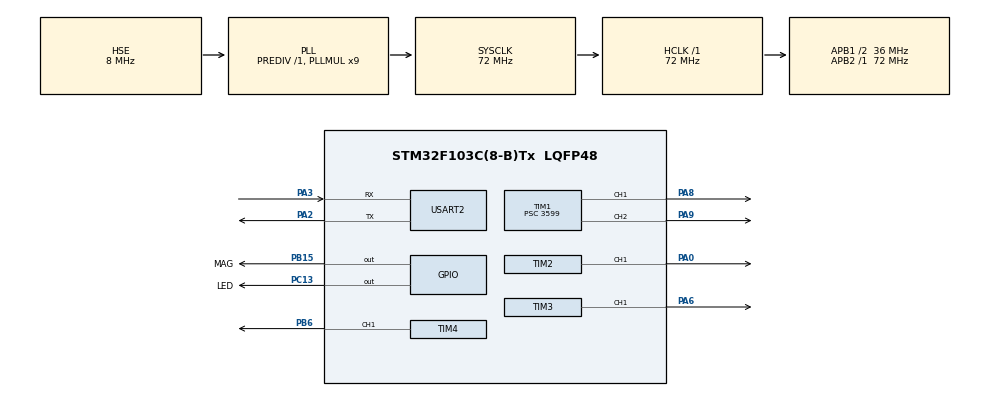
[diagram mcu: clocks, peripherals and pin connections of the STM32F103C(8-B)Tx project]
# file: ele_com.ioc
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Mcu.Family=STM32F1
Mcu.Name=STM32F103C(8-B)Tx
Mcu.Package=LQFP48
NVIC.PriorityGroup=NVIC_PRIORITYGROUP_4
NVIC.USART2_IRQn=true\:0\:0\:true\:false\:true\:true\:true\:true
PA0-WKUP.Signal=S_TIM2_CH1_ETR
PA13.Mode=Serial_Wire
PA13.Signal=SYS_JTMS-SWDIO
PA14.Mode=Serial_Wire
PA14.Signal=SYS_JTCK-SWCLK
PA2.Mode=Asynchronous
PA2.Signal=USART2_TX
PA3.Mode=Asynchronous
PA3.Signal=USART2_RX
PA6.Signal=S_TIM3_CH1
PA8.Signal=S_TIM1_CH1
PA9.Signal=S_TIM1_CH2
PB15.GPIO_Label=MAG
PB15.Signal=GPIO_Output
PB6.Signal=S_TIM4_CH1
PC13-TAMPER-RTC.GPIO_Label=LED
PC13-TAMPER-RTC.PinState=GPIO_PIN_SET
PC13-TAMPER-RTC.Signal=GPIO_Output
PD0-OSC_IN.Mode=HSE-External-Oscillator
PD0-OSC_IN.Signal=RCC_OSC_IN
PD1-OSC_OUT.Mode=HSE-External-Oscillator
PD1-OSC_OUT.Signal=RCC_OSC_OUT
ProjectManager.HeapSize=0x200
ProjectManager.StackSize=0x400
ProjectManager.TargetToolchain=STM32CubeIDE
RCC.AHBFreq_Value=72000000
RCC.APB1CLKDivider=RCC_HCLK_DIV2
RCC.APB1Freq_Value=36000000
RCC.APB1TimFreq_Value=72000000
RCC.APB2Freq_Value=72000000
RCC.APB2TimFreq_Value=72000000
RCC.HCLKFreq_Value=72000000
RCC.PLLMUL=RCC_PLL_MUL9
RCC.PLLSourceVirtual=RCC_PLLSOURCE_HSE
RCC.SYSCLKFreq_VALUE=72000000
RCC.SYSCLKSource=RCC_SYSCLKSOURCE_PLLCLK
RCC.USBFreq_Value=72000000
SH.S_TIM1_CH1.0=TIM1_CH1,PWM Generation1 CH1
SH.S_TIM1_CH2.0=TIM1_CH2,PWM Generation2 CH2
SH.S_TIM2_CH1_ETR.0=TIM2_CH1,PWM Generation1 CH1
SH.S_TIM3_CH1.0=TIM3_CH1,PWM Generation1 CH1
SH.S_TIM4_CH1.0=TIM4_CH1,PWM Generation1 CH1
TIM1.AutoReloadPreload=TIM_AUTORELOAD_PRELOAD_ENABLE
TIM1.Channel-PWM\ Generation1\ CH1=TIM_CHANNEL_1
TIM1.Channel-PWM\ Generation2\ CH2=TIM_CHANNEL_2
TIM1.OCPolarity_2=TIM_OCPOLARITY_LOW
TIM1.Period=399
TIM1.Prescaler=3599
TIM2.Channel-PWM\ Generation1\ CH1=TIM_CHANNEL_1
TIM2.Period=399
TIM2.Prescaler=3599
TIM3.Channel-PWM\ Generation1\ CH1=TIM_CHANNEL_1
TIM3.Period=399
TIM3.Prescaler=3599
TIM4.Channel-PWM\ Generation1\ CH1=TIM_CHANNEL_1
TIM4.Period=399
TIM4.Prescaler=3599
USART2.VirtualMode=VM_ASYNC
board=custom

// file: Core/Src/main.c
/* USER CODE BEGIN Header */
/**
  ******************************************************************************
  * @file           : main.c
  * @brief          : Main program body
  ******************************************************************************
  * @attention
  *
  * Copyright (c) 2024 STMicroelectronics.
  * All rights reserved.
  *
  * This software is licensed under terms that can be found in the LICENSE file
  * in the root directory of this software component.
  * If no LICENSE file comes with this software, it is provided AS-IS.
  *
  ******************************************************************************
  */
/* USER CODE END Header */
#include "main.h"
#include "tim.h"
#include "usart.h"
#include "gpio.h"

/* USER CODE BEGIN Includes */

#include "Kine.h"
#include "servo.h"
#include "stm32f1xx_ll_rcc.h"
/* USER CODE END Includes */

void SystemClock_Config(void);

/* USER CODE BEGIN 0 */
unsigned char data[5] = {0};
/* USER CODE END 0 */

int main(void)
{

  /* MCU Configuration--------------------------------------------------------*/

  /* Reset of all peripherals, Initializes the Flash interface and the Systick. */
  HAL_Init();

  /* Configure the system clock */
  SystemClock_Config();

  /* Initialize all configured peripherals */
  MX_GPIO_Init();
  MX_TIM1_Init();
  MX_TIM2_Init();
  MX_TIM3_Init();
  MX_TIM4_Init();
  MX_USART2_UART_Init();
  /* USER CODE BEGIN 2 */
  Servo_Init();
  HAL_UART_Transmit(&huart2,"enter start to start\n",21,0xff);
  HAL_UART_Receive_IT(&huart2,data,5);
  // unsigned char data[5] = {0};
  // HAL_TIM_PWM_Start(&htim1,TIM_CHANNEL_2);
  /* USER CODE END 2 */

  /* Infinite loop */
  /* USER CODE BEGIN WHILE */
  while (1)
  {
    //Arm_Init();
    Arm_Move_fake(9);
    // __HAL_TIM_SetCompare(&htim1,TIM_CHANNEL_2,99);
    // HAL_UART_Receive(&huart2,data,5,0xff);
    // HAL_Delay(20);
    // HAL_UART_Transmit(&huart2,data,5,0xff);
    // HAL_Delay(200);
    //Arm_Init();
     //Arm_Test();
    // switch (data[0])
    // {
    // case '1':
    //   Arm_Exe_1();
    //   data[0] = 0;
    //   break;
    // case '2':
    //   Arm_Exe_2(data);
    //   data[0] = 0;
    //   break;
    // case '3':
    //   Arm_Exe_3();
    //   break;
    // default:
    //   HAL_GPIO_TogglePin(LED_GPIO_Port,LED_Pin);
    //   HAL_Delay(200);
    //   break;
    // }

    //Arm_Exe();
    //Arm_Init();
    /* USER CODE END WHILE */

  }
}

void SystemClock_Config(void)
{
  RCC_OscInitTypeDef RCC_OscInitStruct = {0};
  RCC_ClkInitTypeDef RCC_ClkInitStruct = {0};

  /** Initializes the RCC Oscillators according to the specified parameters
  * in the RCC_OscInitTypeDef structure.
  */
  RCC_OscInitStruct.OscillatorType = RCC_OSCILLATORTYPE_HSE;
  RCC_OscInitStruct.HSEState = RCC_HSE_ON;
  RCC_OscInitStruct.HSEPredivValue = RCC_HSE_PREDIV_DIV1;
  RCC_OscInitStruct.HSIState = RCC_HSI_ON;
  RCC_OscInitStruct.PLL.PLLState = RCC_PLL_ON;
  RCC_OscInitStruct.PLL.PLLSource = RCC_PLLSOURCE_HSE;
  RCC_OscInitStruct.PLL.PLLMUL = RCC_PLL_MUL9;
  if (HAL_RCC_OscConfig(&RCC_OscInitStruct) != HAL_OK)
  {
    Error_Handler();
  }

  /** Initializes the CPU, AHB and APB buses clocks
  */
  RCC_ClkInitStruct.ClockType = RCC_CLOCKTYPE_HCLK|RCC_CLOCKTYPE_SYSCLK
                              |RCC_CLOCKTYPE_PCLK1|RCC_CLOCKTYPE_PCLK2;
  RCC_ClkInitStruct.SYSCLKSource = RCC_SYSCLKSOURCE_PLLCLK;
  RCC_ClkInitStruct.AHBCLKDivider = RCC_SYSCLK_DIV1;
  RCC_ClkInitStruct.APB1CLKDivider = RCC_HCLK_DIV2;
  RCC_ClkInitStruct.APB2CLKDivider = RCC_HCLK_DIV1;

  if (HAL_RCC_ClockConfig(&RCC_ClkInitStruct, FLASH_LATENCY_2) != HAL_OK)
  {
    Error_Handler();
  }
}

/* USER CODE BEGIN 4 */
void HAL_UART_RxCpltCallback(UART_HandleTypeDef *huart)
{
  if(huart == &huart2)
  {
    HAL_UART_Receive(&huart2,data,5,0xff);
  }
}
/* USER CODE END 4 */

void Error_Handler(void)
{
  __disable_irq();
  while (1)
  {
  }
}
